# LM30XX register map
File version: 1.0
ARM 32-bit Cortex-M0 Microcontroller based device, CPU clock up to 80MHz, etc.
CPU: CM4 r1p0, little endian, no MPU, no FPU, 3 interrupt priority bits
Registers are 32-bit, read-write, reset 0x0 unless marked. A register's access mark holds for its fields unless they carry their own. Offsets are from the block's base; lines under a group give offsets from that group; [hi:lo] are bit positions; {n}, {i} and the like mark numbered series; 'fields as' and 'values as' point back to an identical list; <NAME> marks a mode.

## Memory map
0x40001000 WDT size 0x10 — Watchdog Timer
0xE000E010 SysTick size 0x10 — 24Bit System Tick Timer for use in RTOS

## Interrupts
1 WDT

## SysTick — 24Bit System Tick Timer for use in RTOS
Base 0xE000E010
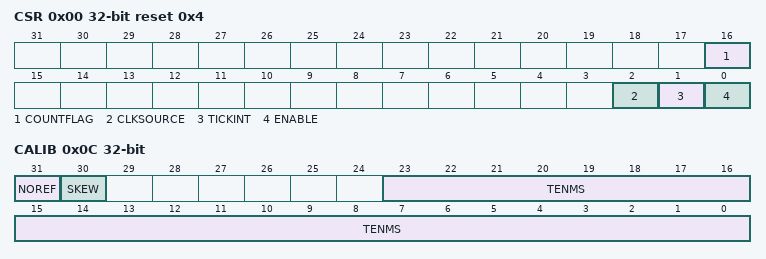
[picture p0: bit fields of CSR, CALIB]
0x00 CSR reset 0x4 — SysTick Control and Status Register
  [16] COUNTFLAG — SysTick counted to zero
  [2] CLKSOURCE — Source to count from
    0=External Clock; 1=CPU Clock
  [1] TICKINT — Generate Tick Interrupt
    0=Enable SysTick Exception; 1=Disable SysTick Exception
  [0] ENABLE — Enable SysTick Timer
    0=disabled; 1=enabled
0x04 RVR — SysTick Reload Value Register
  [23:0] RELOAD — Value to auto reload SysTick after reaching zero
0x08 CVR — SysTick Current Value Register
  [23:0] CURRENT — Current value
0x0C CALIB — SysTick Calibration Value Register
  [31] NOREF ro
    0=Ref Clk available; 1=Ref Clk not available
  [30] SKEW ro — Clock Skew
    0=10ms calibration value is exact; 1=10ms calibration value is inexact, because of the clock frequency
  [23:0] TENMS ro — Reload value to use for 10ms timing

## WDT — Watchdog Timer
Base 0x40001000
0x00 CSR reset 0x4 — Watchdog Control and Status Register
